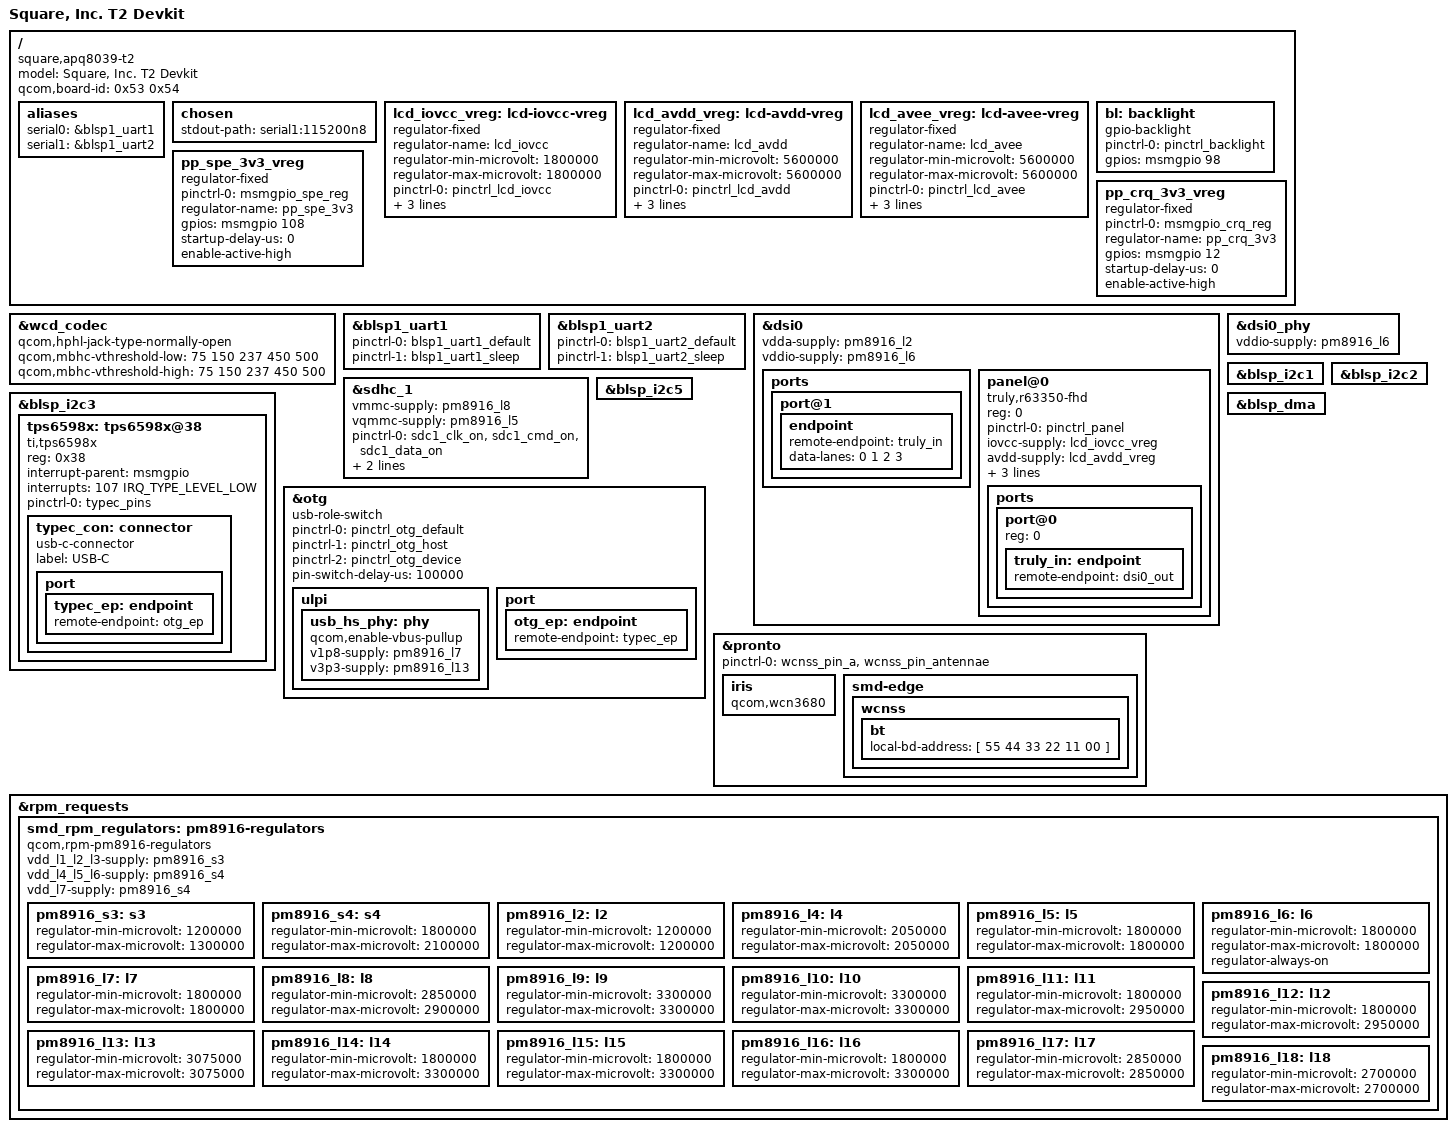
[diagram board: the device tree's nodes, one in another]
// SPDX-License-Identifier: GPL-2.0
/*
 * Copyright (c) 2015, The Linux Foundation. All rights reserved.
 * Copyright (c) 2022, Linaro Ltd.
 *
 * This program is free software; you can redistribute it and/or modify
 * it under the terms of the GNU General Public License version 2 and
 * only version 2 as published by the Free Software Foundation.
 *
 * This program is distributed in the hope that it will be useful,
 * but WITHOUT ANY WARRANTY; without even the implied warranty of
 * MERCHANTABILITY or FITNESS FOR A PARTICULAR PURPOSE.  See the
 * GNU General Public License for more details.
 */

/dts-v1/;

#include "msm8939.dtsi"
#include "pm8916.dtsi"
#include "apq8039-t2-pinctl.dtsi"

/ {
	model = "Square, Inc. T2 Devkit";
	compatible = "square,apq8039-t2", "qcom,msm8939";
	qcom,board-id = <0x53 0x54>;

	aliases {
		serial0 = &blsp1_uart1;
		serial1 = &blsp1_uart2;
	};

	chosen {
		stdout-path = "serial1:115200n8";
	};

	lcd_iovcc_vreg: lcd-iovcc-vreg {
		compatible = "regulator-fixed";
		regulator-name = "lcd_iovcc";
		regulator-min-microvolt = <1800000>;
		regulator-max-microvolt = <1800000>;
		pinctrl-names = "default";
		pinctrl-0 = <&pinctrl_lcd_iovcc>;
		gpios = <&msmgpio 9 GPIO_ACTIVE_HIGH>;
		startup-delay-us = <300>;
		enable-active-high;
	};

	lcd_avdd_vreg: lcd-avdd-vreg {
		compatible = "regulator-fixed";
		regulator-name = "lcd_avdd";
		regulator-min-microvolt = <5600000>;
		regulator-max-microvolt = <5600000>;
		pinctrl-names = "default";
		pinctrl-0 = <&pinctrl_lcd_avdd>;
		gpios = <&msmgpio 86 GPIO_ACTIVE_HIGH>;
		startup-delay-us = <300>;
		enable-active-high;
	};

	lcd_avee_vreg: lcd-avee-vreg {
		compatible = "regulator-fixed";
		regulator-name = "lcd_avee";
		regulator-min-microvolt = <5600000>;
		regulator-max-microvolt = <5600000>;
		pinctrl-names = "default";
		pinctrl-0 = <&pinctrl_lcd_avee>;
		gpios = <&msmgpio 87 GPIO_ACTIVE_HIGH>;
		startup-delay-us = <300>;
		enable-active-high;
	};

	bl: backlight {
		compatible = "gpio-backlight";
		pinctrl-names = "default";
		pinctrl-0 = <&pinctrl_backlight>;
		gpios = <&msmgpio 98 GPIO_ACTIVE_HIGH>;
	};

	pp_spe_3v3_vreg: pp_spe_3v3_vreg {
		compatible = "regulator-fixed";
		pinctrl-names = "default";
		pinctrl-0 = <&msmgpio_spe_reg>;
		regulator-name = "pp_spe_3v3";
		gpios = <&msmgpio 108 GPIO_ACTIVE_HIGH>;
		startup-delay-us = <0>;
		enable-active-high;
	};

	pp_crq_3v3_vreg: pp_crq_3v3_vreg {
		compatible = "regulator-fixed";
		pinctrl-names = "default";
		pinctrl-0 = <&msmgpio_crq_reg>;
		regulator-name = "pp_crq_3v3";
		gpios = <&msmgpio 12 GPIO_ACTIVE_HIGH>;
		startup-delay-us = <0>;
		enable-active-high;
	};
};

&wcd_codec {
	status = "okay";
	qcom,hphl-jack-type-normally-open;
	qcom,mbhc-vthreshold-low = <75 150 237 450 500>;
	qcom,mbhc-vthreshold-high = <75 150 237 450 500>;
};

&blsp1_uart1 {
	pinctrl-names = "default", "sleep";
	pinctrl-0 = <&blsp1_uart1_default>;
	pinctrl-1 = <&blsp1_uart1_sleep>;
	status = "okay";
};

&blsp1_uart2 {
	pinctrl-names = "default", "sleep";
	pinctrl-0 = <&blsp1_uart2_default>;
	pinctrl-1 = <&blsp1_uart2_sleep>;
	status = "okay";
};

&dsi0 {
	#address-cells = <1>;
	#size-cells = <0>;
	vdda-supply = <&pm8916_l2>;
	vddio-supply = <&pm8916_l6>;
	status = "okay";

	ports {
		port@1 {
			endpoint {
				remote-endpoint = <&truly_in>;
				data-lanes = <0 1 2 3>;
			};
		};
	};

	panel@0 {
		compatible = "truly,r63350-fhd";
		reg = <0>;
		pinctrl-names = "default";
		pinctrl-0 = <&pinctrl_panel>;
		iovcc-supply = <&lcd_iovcc_vreg>;
		avdd-supply = <&lcd_avdd_vreg>;
		avee-supply = <&lcd_avee_vreg>;
		reset-gpios = <&msmgpio 25 GPIO_ACTIVE_LOW>;
		backlight = <&bl>;

		ports {
			#address-cells = <1>;
			#size-cells = <0>;

			port@0 {
				reg = <0>;
				truly_in: endpoint {
					remote-endpoint = <&dsi0_out>;
				};
			};
		};
	};

};

&dsi0_phy {
	vddio-supply = <&pm8916_l6>;
	status = "okay";
};

&sdhc_1 {
	vmmc-supply = <&pm8916_l8>;
	vqmmc-supply = <&pm8916_l5>;

	pinctrl-names = "default", "sleep";
	pinctrl-0 = <&sdc1_clk_on &sdc1_cmd_on &sdc1_data_on>;
	pinctrl-1 = <&sdc1_clk_off &sdc1_cmd_off &sdc1_data_off>;
	status = "okay";
};

&blsp_i2c1 {
	status = "okay";
};

&blsp_i2c2 {
	status = "okay";
};

&blsp_i2c3 {
	status = "okay";
	tps6598x: tps6598x@38 {
		compatible = "ti,tps6598x";
		reg = <0x38>;

		interrupt-parent = <&msmgpio>;
		interrupts = <107 IRQ_TYPE_LEVEL_LOW>;
		interrupt-names = "irq";

		pinctrl-names = "default";
		pinctrl-0 = <&typec_pins>;

		typec_con: connector {
			compatible = "usb-c-connector";
			label = "USB-C";
			port {
				typec_ep: endpoint {
					remote-endpoint = <&otg_ep>;
				};
			};
		};
	};
};

&blsp_i2c5 {
	status = "okay";
};

&blsp_dma {
	status = "okay";
};

&otg {
	status = "okay";
	usb-role-switch;

	pinctrl-names = "default", "host", "device";
	pinctrl-0 = <&pinctrl_otg_default>;
	pinctrl-1 = <&pinctrl_otg_host>;
	pinctrl-2 = <&pinctrl_otg_device>;
	pin-switch-delay-us = <100000>;

	ulpi {
		usb_hs_phy: phy {
			qcom,enable-vbus-pullup;
			v1p8-supply = <&pm8916_l7>;
			v3p3-supply = <&pm8916_l13>;
		};
	};
	port {
		otg_ep: endpoint {
			remote-endpoint = <&typec_ep>;
		};
	};
};

&pronto {
	pinctrl-names = "default";
	pinctrl-0 = <&wcnss_pin_a &wcnss_pin_antennae>;
	status = "okay";

	iris {
		compatible = "qcom,wcn3680";
	};

	smd-edge {
		wcnss {
			bt {
				local-bd-address = [ 55 44 33 22 11 00 ];
			};
		};
	};
};

&rpm_requests {
	smd_rpm_regulators: pm8916-regulators {
		compatible = "qcom,rpm-pm8916-regulators";
		vdd_l1_l2_l3-supply = <&pm8916_s3>;
		vdd_l4_l5_l6-supply = <&pm8916_s4>;
		vdd_l7-supply = <&pm8916_s4>;

		pm8916_s3: s3 {
			regulator-min-microvolt = <1200000>;
			regulator-max-microvolt = <1300000>;
		};

		pm8916_s4: s4 {
			regulator-min-microvolt = <1800000>;
			regulator-max-microvolt = <2100000>;
		};

		/* l1 is fixed to 1225000, but not connected in schematic */
		pm8916_l2: l2 {
			regulator-min-microvolt = <1200000>;
			regulator-max-microvolt = <1200000>;
		};

		pm8916_l4: l4 {
			regulator-min-microvolt = <2050000>;
			regulator-max-microvolt = <2050000>;
		};

		pm8916_l5: l5 {
			regulator-min-microvolt = <1800000>;
			regulator-max-microvolt = <1800000>;
		};

		pm8916_l6: l6 {
			regulator-min-microvolt = <1800000>;
			regulator-max-microvolt = <1800000>;
			regulator-always-on; /* copy from v3.10 */
		};

		pm8916_l7: l7 {
			regulator-min-microvolt = <1800000>;
			regulator-max-microvolt = <1800000>;
		};

		pm8916_l8: l8 {
			regulator-min-microvolt = <2850000>;
			regulator-max-microvolt = <2900000>;
		};

		pm8916_l9: l9 {
			regulator-min-microvolt = <3300000>;
			regulator-max-microvolt = <3300000>;
		};

		pm8916_l10: l10 {
			regulator-min-microvolt = <3300000>;
			regulator-max-microvolt = <3300000>;
		};

		pm8916_l11: l11 {
			regulator-min-microvolt = <1800000>;
			regulator-max-microvolt = <2950000>;
		};

		pm8916_l12: l12 {
			regulator-min-microvolt = <1800000>;
			regulator-max-microvolt = <2950000>;
		};

		pm8916_l13: l13 {
			regulator-min-microvolt = <3075000>;
			regulator-max-microvolt = <3075000>;
		};

		pm8916_l14: l14 {
			regulator-min-microvolt = <1800000>;
			regulator-max-microvolt = <3300000>;
		};

		pm8916_l15: l15 {
			regulator-min-microvolt = <1800000>;
			regulator-max-microvolt = <3300000>;
		};

		pm8916_l16: l16 {
			regulator-min-microvolt = <1800000>;
			regulator-max-microvolt = <3300000>;
		};

		pm8916_l17: l17 {
			regulator-min-microvolt = <2850000>;
			regulator-max-microvolt = <2850000>;
		};

		pm8916_l18: l18 {
			regulator-min-microvolt = <2700000>;
			regulator-max-microvolt = <2700000>;
		};
	};
};
